# AE350_4GB register map
Vendor: Andes Technology; Series: AE350; File version: 1.3.0
Generated from Andes AE350-4GB.regs
Registers are 32-bit, read-write, reset 0x0 unless marked. A register's access mark holds for its fields unless they carry their own. Offsets are from the block's base; lines under a group give offsets from that group; [hi:lo] are bit positions; {n}, {i} and the like mark numbered series; 'fields as' and 'values as' point back to an identical list; <NAME> marks a mode.

## Memory map
0xC0000000 BMC — AXI Bus Interconnector Registers
0xE0000000 AHB_decoder — AHB-Lite decoder Registers
0xE4000000 PLIC — Platform-Level Interrupt Controller
0xE4000000 PLIC_IntSrc1_127Priority — Platform-Level Interrupt Controller
0xE4000000 PLIC_IntSrc128_255Priority — Platform-Level Interrupt Controller
0xE4000000 PLIC_IntSrc256_383Priority — Platform-Level Interrupt Controller
0xE4000000 PLIC_IntSrc384_511Priority — Platform-Level Interrupt Controller
0xE4000000 PLIC_IntSrc512_639Priority — Platform-Level Interrupt Controller
0xE4000000 PLIC_IntSrc640_767Priority — Platform-Level Interrupt Controller
0xE4000000 PLIC_IntSrc768_895Priority — Platform-Level Interrupt Controller
0xE4000000 PLIC_IntSrc896_1023Priority — Platform-Level Interrupt Controller
0xE4000000 PLIC_IntPending — Platform-Level Interrupt Controller
0xE4000000 PLIC_IntTriggerType — Platform-Level Interrupt Controller
0xE4000000 PLIC_NumIntTarget_Version — Platform-Level Interrupt Controller
0xE4000000 PLIC_Target0_3IntEnableBits — Platform-Level Interrupt Controller
0xE4000000 PLIC_Target4_7IntEnableBits — Platform-Level Interrupt Controller
0xE4000000 PLIC_Target8_11IntEnableBits — Platform-Level Interrupt Controller
0xE4000000 PLIC_Target12_15IntEnableBits — Platform-Level Interrupt Controller
0xE4000000 PLIC_Target0_3 — Platform-Level Interrupt Controller
0xE4000000 PLIC_Target4_7 — Platform-Level Interrupt Controller
0xE4000000 PLIC_Target8_11 — Platform-Level Interrupt Controller
0xE4000000 PLIC_Target12_15 — Platform-Level Interrupt Controller
0xE6000000 PLMT — Platform-Level Machine Timer
0xE6800000 PLDM — Platform-Level Debug Module
0xF0000000 APB_Bridge — APB Bridge Registers
0xF0100000 SMU — System Management Unit Registers
0xF0200000 UART1 — UART1 Controller Registers
0xF0300000 UART2 — UART2 Controller Registers
0xF0400000 PIT — PIT Controller Registers
0xF0500000 WDT — WDT Controller Registers
0xF0600000 RTC — RTC Controller Registers
0xF0700000 GPIO — GPIO Controller Registers
0xF0A00000 I_2C — I^2C Controller Registers
0xF0C00000 DMAC — DMA Controller Registers
0xF0F00000 SPI2 — SPI2 Controller Registers

## BMC — AXI Bus Interconnector Registers
Base 0xC0000000
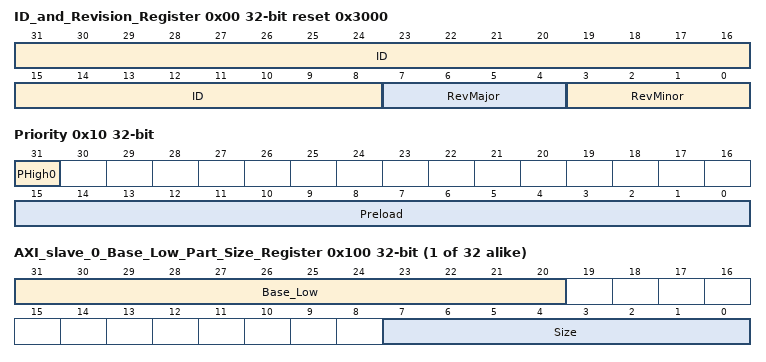
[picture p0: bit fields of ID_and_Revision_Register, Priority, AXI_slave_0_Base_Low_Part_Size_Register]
0x00 ID_and_Revision_Register reset 0x3000
  [31:8] ID ro — ID number for ATCBMC300
  [7:4] RevMajor ro — Major revision number
  [3:0] RevMinor ro — Minor revision number
0x10 Priority
  [31] PHigh0 — Master 0 is the highest priority master
  [15:0] Preload — Priority level for corresponding masters
{0x100+8i} AXI_slave_{i}_Base_Low_Part_Size_Register (i=0..31)
  [31:20] Base_Low ro — Bits [31:20] of the configured base address
  [7:0] Size ro
{0x104+8i} AXI_slave_{i}_Base_High_Part_Register (i=0..31)
  [31:0] Base_High ro — Bits [63:32] of the configured base address

## AHB_decoder — AHB-Lite decoder Registers
Base 0xE0000000
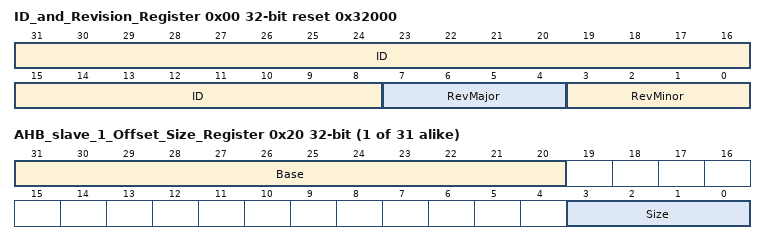
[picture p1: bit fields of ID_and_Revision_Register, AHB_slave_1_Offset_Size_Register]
0x00 ID_and_Revision_Register ro reset 0x32000
  [31:8] ID — ID number for ATCBUSDEC200
  [7:4] RevMajor — Major revision number
  [3:0] RevMinor — Minor revision number
{0x1C+4i} AHB_slave_{i}_Offset_Size_Register (i=1..31)
  [31:20] Base ro — Base address
  [3:0] Size ro — Size of the address space

## PLIC — Platform-Level Interrupt Controller
Base 0xE4000000
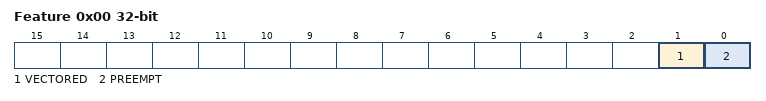
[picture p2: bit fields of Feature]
0x00 Feature — Feature enable register
  [1] VECTORED — Enable vectored mode for PLIC
  [0] PREEMPT — Preemptive priority interrupt enable

## PLIC_IntSrc1_127Priority — Platform-Level Interrupt Controller
Base 0xE4000000
{0x0+4i} IntSrc{i}Priority reset 0x1 (i=1..127) — Interrupt Source {i} Priority
  [?] FIELD_1
